AUTOSAR XML (schema 314)
package /ComponentType
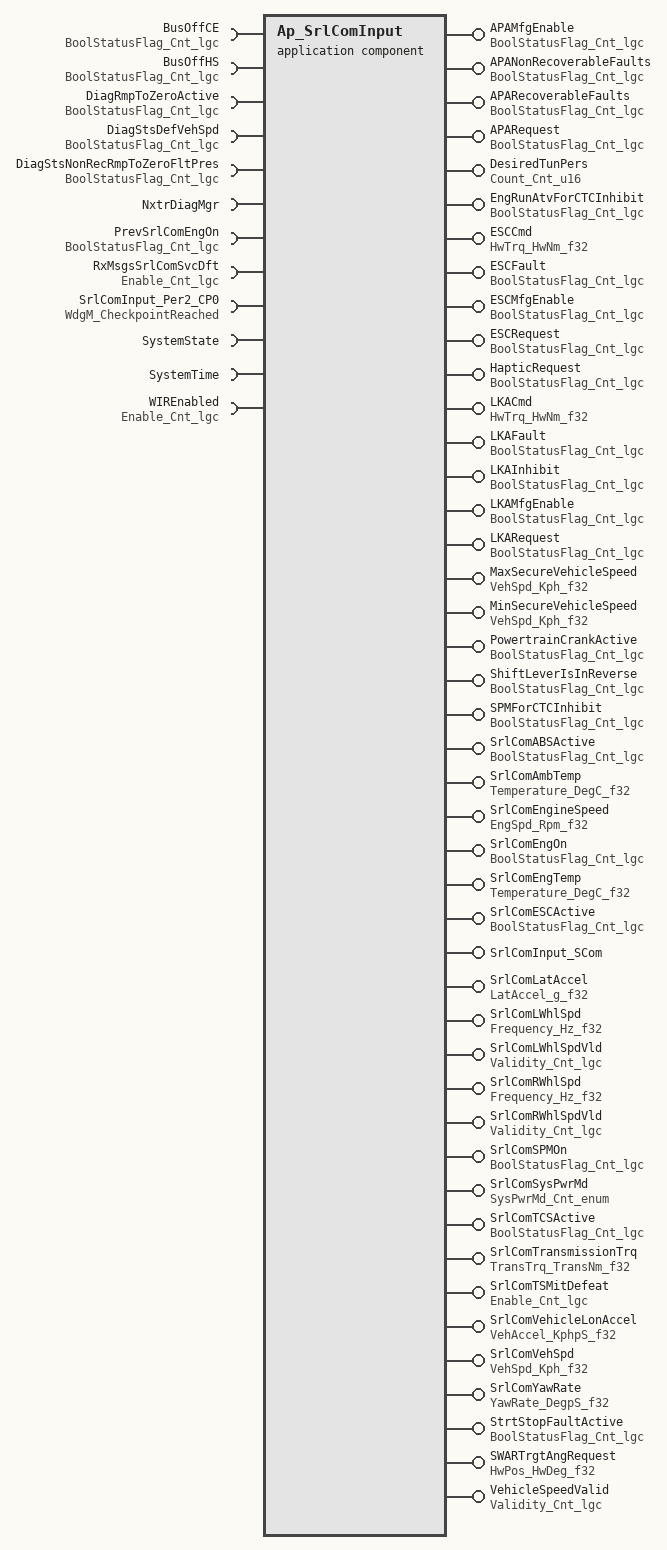
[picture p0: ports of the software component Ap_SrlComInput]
  application software component type Ap_SrlComInput
    44 x provide port:
      APAMfgEnable: unqueued-sender-com-spec{data-element=Cnt_lgc, can-invalidate=false, init-value=D_FALSE_CNT_LGC}, provided-interface=BoolStatusFlag_Cnt_lgc
      APANonRecoverableFaults: unqueued-sender-com-spec{data-element=Cnt_lgc, can-invalidate=false, init-value=D_FALSE_CNT_LGC}, provided-interface=BoolStatusFlag_Cnt_lgc
      APARecoverableFaults: unqueued-sender-com-spec{data-element=Cnt_lgc, can-invalidate=false, init-value=D_FALSE_CNT_LGC}, provided-interface=BoolStatusFlag_Cnt_lgc
      APARequest: unqueued-sender-com-spec{data-element=Cnt_lgc, can-invalidate=false, init-value=D_FALSE_CNT_LGC}, provided-interface=BoolStatusFlag_Cnt_lgc
      DesiredTunPers: unqueued-sender-com-spec{data-element=Cnt_u16, can-invalidate=false, init-value=D_ZERO_CNT_U16}, provided-interface=Count_Cnt_u16
      EngRunAtvForCTCInhibit: unqueued-sender-com-spec{data-element=Cnt_lgc, can-invalidate=false, init-value=D_FALSE_CNT_LGC}, provided-interface=BoolStatusFlag_Cnt_lgc
      ESCCmd: unqueued-sender-com-spec{data-element=HwNm_f32, can-invalidate=false, init-value=D_ZERO_ULS_F32}, provided-interface=HwTrq_HwNm_f32
      ESCFault: unqueued-sender-com-spec{data-element=Cnt_lgc, can-invalidate=false, init-value=D_FALSE_CNT_LGC}, provided-interface=BoolStatusFlag_Cnt_lgc
      ESCMfgEnable: unqueued-sender-com-spec{data-element=Cnt_lgc, can-invalidate=false, init-value=D_FALSE_CNT_LGC}, provided-interface=BoolStatusFlag_Cnt_lgc
      ESCRequest: unqueued-sender-com-spec{data-element=Cnt_lgc, can-invalidate=false, init-value=D_FALSE_CNT_LGC}, provided-interface=BoolStatusFlag_Cnt_lgc
      HapticRequest: unqueued-sender-com-spec{data-element=Cnt_lgc, can-invalidate=false, init-value=D_FALSE_CNT_LGC}, provided-interface=BoolStatusFlag_Cnt_lgc
      LKACmd: unqueued-sender-com-spec{data-element=HwNm_f32, can-invalidate=false, init-value=D_ZERO_ULS_F32}, provided-interface=HwTrq_HwNm_f32
      LKAFault: unqueued-sender-com-spec{data-element=Cnt_lgc, can-invalidate=false, init-value=D_FALSE_CNT_LGC}, provided-interface=BoolStatusFlag_Cnt_lgc
      LKAInhibit: unqueued-sender-com-spec{data-element=Cnt_lgc, can-invalidate=false, init-value=D_FALSE_CNT_LGC}, provided-interface=BoolStatusFlag_Cnt_lgc
      LKAMfgEnable: unqueued-sender-com-spec{data-element=Cnt_lgc, can-invalidate=false, init-value=D_FALSE_CNT_LGC}, provided-interface=BoolStatusFlag_Cnt_lgc
      LKARequest: unqueued-sender-com-spec{data-element=Cnt_lgc, can-invalidate=false, init-value=D_FALSE_CNT_LGC}, provided-interface=BoolStatusFlag_Cnt_lgc
      MaxSecureVehicleSpeed: unqueued-sender-com-spec{data-element=Kph_f32, can-invalidate=false, init-value=D_ZERO_ULS_F32}, provided-interface=VehSpd_Kph_f32
      MinSecureVehicleSpeed: unqueued-sender-com-spec{data-element=Kph_f32, can-invalidate=false, init-value=D_ZERO_ULS_F32}, provided-interface=VehSpd_Kph_f32
      PowertrainCrankActive: unqueued-sender-com-spec{data-element=Cnt_lgc, can-invalidate=false, init-value=D_FALSE_CNT_LGC}, provided-interface=BoolStatusFlag_Cnt_lgc
      ShiftLeverIsInReverse: unqueued-sender-com-spec{data-element=Cnt_lgc, can-invalidate=false, init-value=D_FALSE_CNT_LGC}, provided-interface=BoolStatusFlag_Cnt_lgc
      SPMForCTCInhibit: unqueued-sender-com-spec{data-element=Cnt_lgc, can-invalidate=false, init-value=D_FALSE_CNT_LGC}, provided-interface=BoolStatusFlag_Cnt_lgc
      SrlComABSActive: unqueued-sender-com-spec{data-element=Cnt_lgc, can-invalidate=false, init-value=D_FALSE_CNT_LGC}, provided-interface=BoolStatusFlag_Cnt_lgc
      SrlComAmbTemp: unqueued-sender-com-spec{data-element=DegC_f32, can-invalidate=false, init-value=D_ZERO_ULS_F32}, provided-interface=Temperature_DegC_f32
      SrlComEngineSpeed: unqueued-sender-com-spec{data-element=Rpm_f32, can-invalidate=false, init-value=D_ZERO_ULS_F32}, provided-interface=EngSpd_Rpm_f32
      SrlComEngOn: unqueued-sender-com-spec{data-element=Cnt_lgc, can-invalidate=false, init-value=D_FALSE_CNT_LGC}, provided-interface=BoolStatusFlag_Cnt_lgc
      SrlComEngTemp: unqueued-sender-com-spec{data-element=DegC_f32, can-invalidate=false, init-value=D_ZERO_ULS_F32}, provided-interface=Temperature_DegC_f32
      SrlComESCActive: unqueued-sender-com-spec{data-element=Cnt_lgc, can-invalidate=false, init-value=D_FALSE_CNT_LGC}, provided-interface=BoolStatusFlag_Cnt_lgc
      SrlComInput_SCom: provided-interface=SrlComInput_SCom
        provided-com-specs:
          operation=GetSrlComWIRFltStatus, queue-length=1
          operation=ManualVehSpd, queue-length=1
          operation=ResetBus1Timers, queue-length=1
          operation=ResetBus2Timers, queue-length=1
      SrlComLatAccel: unqueued-sender-com-spec{data-element=g_f32, can-invalidate=false, init-value=D_ZERO_ULS_F32}, provided-interface=LatAccel_g_f32
      SrlComLWhlSpd: unqueued-sender-com-spec{data-element=Hz_f32, can-invalidate=false, init-value=D_ZERO_ULS_F32}, provided-interface=Frequency_Hz_f32
      SrlComLWhlSpdVld: unqueued-sender-com-spec{data-element=Cnt_lgc, can-invalidate=false, init-value=D_FALSE_CNT_LGC}, provided-interface=Validity_Cnt_lgc
      SrlComRWhlSpd: unqueued-sender-com-spec{data-element=Hz_f32, can-invalidate=false, init-value=D_ZERO_ULS_F32}, provided-interface=Frequency_Hz_f32
      SrlComRWhlSpdVld: unqueued-sender-com-spec{data-element=Cnt_lgc, can-invalidate=false, init-value=D_FALSE_CNT_LGC}, provided-interface=Validity_Cnt_lgc
      SrlComSPMOn: unqueued-sender-com-spec{data-element=Cnt_lgc, can-invalidate=false, init-value=D_FALSE_CNT_LGC}, provided-interface=BoolStatusFlag_Cnt_lgc
      SrlComSysPwrMd: unqueued-sender-com-spec{data-element=Cnt_enum, can-invalidate=false, init-value=D_SYSPWRMODESTATEINIT_CNT_ENUM}, provided-interface=SysPwrMd_Cnt_enum
      SrlComTCSActive: unqueued-sender-com-spec{data-element=Cnt_lgc, can-invalidate=false, init-value=D_FALSE_CNT_LGC}, provided-interface=BoolStatusFlag_Cnt_lgc
      SrlComTransmissionTrq: unqueued-sender-com-spec{data-element=TransNm_f32, can-invalidate=false, init-value=D_ZERO_ULS_F32}, provided-interface=TransTrq_TransNm_f32
      SrlComTSMitDefeat: unqueued-sender-com-spec{data-element=Cnt_lgc, can-invalidate=false, init-value=D_FALSE_CNT_LGC}, provided-interface=Enable_Cnt_lgc
      SrlComVehicleLonAccel: unqueued-sender-com-spec{data-element=KphpS_f32, can-invalidate=false, init-value=D_ZERO_ULS_F32}, provided-interface=VehAccel_KphpS_f32
      SrlComVehSpd: unqueued-sender-com-spec{data-element=Kph_f32, can-invalidate=false, init-value=D_ZERO_ULS_F32}, provided-interface=VehSpd_Kph_f32
      SrlComYawRate: unqueued-sender-com-spec{data-element=DegpS_f32, can-invalidate=false, init-value=D_ZERO_ULS_F32}, provided-interface=YawRate_DegpS_f32
      StrtStopFaultActive: unqueued-sender-com-spec{data-element=Cnt_lgc, can-invalidate=false, init-value=D_FALSE_CNT_LGC}, provided-interface=BoolStatusFlag_Cnt_lgc
      SWARTrgtAngRequest: unqueued-sender-com-spec{data-element=HwDeg_f32, can-invalidate=false, init-value=D_ZERO_ULS_F32}, provided-interface=HwPos_HwDeg_f32
      VehicleSpeedValid: unqueued-sender-com-spec{data-element=Cnt_lgc, can-invalidate=false, init-value=D_FALSE_CNT_LGC}, provided-interface=Validity_Cnt_lgc
    12 x require port:
      BusOffCE: unqueued-receiver-com-spec{data-element=Cnt_lgc, init-value=D_FALSE_CNT_LGC}, required-interface=BoolStatusFlag_Cnt_lgc
      BusOffHS: unqueued-receiver-com-spec{data-element=Cnt_lgc, init-value=D_FALSE_CNT_LGC}, required-interface=BoolStatusFlag_Cnt_lgc
      DiagRmpToZeroActive: unqueued-receiver-com-spec{data-element=Cnt_lgc, init-value=D_FALSE_CNT_LGC}, required-interface=BoolStatusFlag_Cnt_lgc
      DiagStsDefVehSpd: unqueued-receiver-com-spec{data-element=Cnt_lgc, init-value=D_FALSE_CNT_LGC}, required-interface=BoolStatusFlag_Cnt_lgc
      DiagStsNonRecRmpToZeroFltPres: unqueued-receiver-com-spec{data-element=Cnt_lgc, init-value=D_FALSE_CNT_LGC}, required-interface=BoolStatusFlag_Cnt_lgc
      NxtrDiagMgr: required-com-specs=[GetNTCActive, GetNTCFailed, GetNTCStatus, SetNTCStatus], required-interface=NxtrDiagMgr
      PrevSrlComEngOn: unqueued-receiver-com-spec{data-element=Cnt_lgc, init-value=D_FALSE_CNT_LGC}, required-interface=BoolStatusFlag_Cnt_lgc
      RxMsgsSrlComSvcDft: unqueued-receiver-com-spec{data-element=Cnt_lgc, init-value=D_FALSE_CNT_LGC}, required-interface=Enable_Cnt_lgc
      SrlComInput_Per2_CP0: client-com-spec=CheckpointReached, required-interface=WdgM_CheckpointReached
      SystemState: required-interface=SystemState
      SystemTime: required-interface=SystemTime
        required-com-specs:
          DtrmnElapsedTime_mS_u16
          DtrmnElapsedTime_mS_u32
          DtrmnElapsedTime_uS_u16
          DtrmnElapsedTime_uS_u32
          GetSystemTime_mS_u32
          GetSystemTime_uS_u32
      WIREnabled: unqueued-receiver-com-spec{data-element=Cnt_lgc, init-value=D_FALSE_CNT_LGC}, required-interface=Enable_Cnt_lgc
  internal behavior Ap_SrlComInput_InternalBehavior: component=Ap_SrlComInput
    4 x timing event:
      SrlComInput_InitEvent: start-on-event=SrlComInput_Init, period=0
      TMT_SrlComInput_Per1: start-on-event=SrlComInput_Per1, period=0.002
      TMT_SrlComInput_Per2: start-on-event=SrlComInput_Per2, period=0.01
      TMT_SrlComInput_Per3: start-on-event=SrlComInput_Per3, period=0.1
    4 x operation invoked event:
      OIT_SrlComInput_SCom_GetSrlComWIRFltStatus_SrlComInput_SCom_GetSrlComWIRFltStatus: start-on-event=SrlComInput_SCom_GetSrlComWIRFltStatus, operation=SrlComInput_SCom.GetSrlComWIRFltStatus
      OIT_SrlComInput_SCom_ManualVehSpd_SrlComInput_SCom_ManualVehSpd: start-on-event=SrlComInput_SCom_ManualVehSpd, operation=SrlComInput_SCom.ManualVehSpd
      OIT_SrlComInput_SCom_ResetBus1Timers_SrlComInput_SCom_ResetBus1Timers: start-on-event=SrlComInput_SCom_ResetBus1Timers, operation=SrlComInput_SCom.ResetBus1Timers
      OIT_SrlComInput_SCom_ResetBus2Timers_SrlComInput_SCom_ResetBus2Timers: start-on-event=SrlComInput_SCom_ResetBus2Timers, operation=SrlComInput_SCom.ResetBus2Timers
    port-api-options:
      enable-take-address=false, indirect-api=false, port=APAMfgEnable
      enable-take-address=false, indirect-api=false, port=APANonRecoverableFaults
      enable-take-address=false, indirect-api=false, port=APARecoverableFaults
      enable-take-address=false, indirect-api=false, port=APARequest
      enable-take-address=false, indirect-api=false, port=BusOffCE
      enable-take-address=false, indirect-api=false, port=BusOffHS
      enable-take-address=false, indirect-api=false, port=DesiredTunPers
      enable-take-address=false, indirect-api=false, port=DiagRmpToZeroActive
      enable-take-address=false, indirect-api=false, port=DiagStsDefVehSpd
      enable-take-address=false, indirect-api=false, port=DiagStsNonRecRmpToZeroFltPres
      enable-take-address=false, indirect-api=false, port=EngRunAtvForCTCInhibit
      enable-take-address=false, indirect-api=false, port=ESCCmd
      enable-take-address=false, indirect-api=false, port=ESCFault
      enable-take-address=false, indirect-api=false, port=ESCMfgEnable
      enable-take-address=false, indirect-api=false, port=ESCRequest
      enable-take-address=false, indirect-api=false, port=HapticRequest
      enable-take-address=false, indirect-api=false, port=LKACmd
      enable-take-address=false, indirect-api=false, port=LKAFault
      enable-take-address=false, indirect-api=false, port=LKAInhibit
      enable-take-address=false, indirect-api=false, port=LKAMfgEnable
      enable-take-address=false, indirect-api=false, port=LKARequest
      enable-take-address=false, indirect-api=false, port=MaxSecureVehicleSpeed
      enable-take-address=false, indirect-api=false, port=MinSecureVehicleSpeed
      enable-take-address=false, indirect-api=false, port=NxtrDiagMgr
      enable-take-address=false, indirect-api=false, port=PowertrainCrankActive
      enable-take-address=false, indirect-api=false, port=PrevSrlComEngOn
      enable-take-address=false, indirect-api=false, port=RxMsgsSrlComSvcDft
      enable-take-address=false, indirect-api=false, port=ShiftLeverIsInReverse
      enable-take-address=false, indirect-api=false, port=SPMForCTCInhibit
      enable-take-address=false, indirect-api=false, port=SrlComABSActive
      enable-take-address=false, indirect-api=false, port=SrlComAmbTemp
      enable-take-address=false, indirect-api=false, port=SrlComEngineSpeed
      enable-take-address=false, indirect-api=false, port=SrlComEngOn
      enable-take-address=false, indirect-api=false, port=SrlComEngTemp
      enable-take-address=false, indirect-api=false, port=SrlComESCActive
      enable-take-address=false, indirect-api=false, port=SrlComInput_Per2_CP0
      enable-take-address=false, indirect-api=false, port=SrlComInput_SCom
      enable-take-address=false, indirect-api=false, port=SrlComLatAccel
      enable-take-address=false, indirect-api=false, port=SrlComLWhlSpd
      enable-take-address=false, indirect-api=false, port=SrlComLWhlSpdVld
      enable-take-address=false, indirect-api=false, port=SrlComRWhlSpd
      enable-take-address=false, indirect-api=false, port=SrlComRWhlSpdVld
      enable-take-address=false, indirect-api=false, port=SrlComSPMOn
      enable-take-address=false, indirect-api=false, port=SrlComSysPwrMd
      enable-take-address=false, indirect-api=false, port=SrlComTCSActive
      enable-take-address=false, indirect-api=false, port=SrlComTransmissionTrq
      enable-take-address=false, indirect-api=false, port=SrlComTSMitDefeat
      enable-take-address=false, indirect-api=false, port=SrlComVehicleLonAccel
      enable-take-address=false, indirect-api=false, port=SrlComVehSpd
      enable-take-address=false, indirect-api=false, port=SrlComYawRate
      enable-take-address=false, indirect-api=false, port=StrtStopFaultActive
      enable-take-address=false, indirect-api=false, port=SWARTrgtAngRequest
      enable-take-address=false, indirect-api=false, port=SystemState
      enable-take-address=false, indirect-api=false, port=SystemTime
      enable-take-address=false, indirect-api=false, port=VehicleSpeedValid
      enable-take-address=false, indirect-api=false, port=WIREnabled
    8 x runnable:
      SrlComInput_Init
        data send point SEND_SrlComAmbTemp_DegC_f32: data-element=SrlComAmbTemp.DegC_f32
        data send point SEND_SrlComEngTemp_DegC_f32: data-element=SrlComEngTemp.DegC_f32
        data send point SEND_SrlComVehicleLonAccel_KphpS_f32: data-element=SrlComVehicleLonAccel.KphpS_f32
      SrlComInput_Per1
        data receive point REC_RxMsgsSrlComSvcDft_Cnt_lgc: data-element=RxMsgsSrlComSvcDft.Cnt_lgc
        data receive point REC_WIREnabled_Cnt_lgc: data-element=WIREnabled.Cnt_lgc
        9 x data send point:
          SEND_LKACmd_HwNm_f32: data-element=LKACmd.HwNm_f32
          SEND_LKAFault_Cnt_lgc: data-element=LKAFault.Cnt_lgc
          SEND_LKAInhibit_Cnt_lgc: data-element=LKAInhibit.Cnt_lgc
          SEND_LKARequest_Cnt_lgc: data-element=LKARequest.Cnt_lgc
          SEND_MaxSecureVehicleSpeed_Kph_f32: data-element=MaxSecureVehicleSpeed.Kph_f32
          SEND_SrlComLWhlSpd_Hz_f32: data-element=SrlComLWhlSpd.Hz_f32
          SEND_SrlComLWhlSpdVld_Cnt_lgc: data-element=SrlComLWhlSpdVld.Cnt_lgc
          SEND_SrlComRWhlSpd_Hz_f32: data-element=SrlComRWhlSpd.Hz_f32
          SEND_SrlComRWhlSpdVld_Cnt_lgc: data-element=SrlComRWhlSpdVld.Cnt_lgc
        sync call SC_NxtrDiagMgr_GetNTCStatus: operation=NxtrDiagMgr.GetNTCStatus, timeout=0
        sync call SC_NxtrDiagMgr_SetNTCStatus: operation=NxtrDiagMgr.SetNTCStatus, timeout=0
        sync call SC_SystemTime_GetSystemTime_mS_u32: operation=SystemTime.GetSystemTime_mS_u32, timeout=0
      SrlComInput_Per2
        data read access READ_BusOffCE_Cnt_lgc: data-element=BusOffCE.Cnt_lgc
        data read access READ_BusOffHS_Cnt_lgc: data-element=BusOffHS.Cnt_lgc
        4 x data receive point:
          REC_DiagRmpToZeroActive_Cnt_lgc: data-element=DiagRmpToZeroActive.Cnt_lgc
          REC_DiagStsNonRecRmpToZeroFltPres_Cnt_lgc: data-element=DiagStsNonRecRmpToZeroFltPres.Cnt_lgc
          REC_RxMsgsSrlComSvcDft_Cnt_lgc: data-element=RxMsgsSrlComSvcDft.Cnt_lgc
          REC_WIREnabled_Cnt_lgc: data-element=WIREnabled.Cnt_lgc
        37 x data send point:
          SEND_APAMfgEnable_Cnt_lgc: data-element=APAMfgEnable.Cnt_lgc
          SEND_APANonRecoverableFaults_Cnt_lgc: data-element=APANonRecoverableFaults.Cnt_lgc
          SEND_APARecoverableFaults_Cnt_lgc: data-element=APARecoverableFaults.Cnt_lgc
          SEND_APARequest_Cnt_lgc: data-element=APARequest.Cnt_lgc
          SEND_DesiredTunPers_Cnt_u16: data-element=DesiredTunPers.Cnt_u16
          SEND_EngRunAtvForCTCInhibit_Cnt_lgc: data-element=EngRunAtvForCTCInhibit.Cnt_lgc
          SEND_ESCCmd_HwNm_f32: data-element=ESCCmd.HwNm_f32
          SEND_ESCFault_Cnt_lgc: data-element=ESCFault.Cnt_lgc
          SEND_ESCMfgEnable_Cnt_lgc: data-element=ESCMfgEnable.Cnt_lgc
          SEND_ESCRequest_Cnt_lgc: data-element=ESCRequest.Cnt_lgc
          SEND_HapticRequest_Cnt_lgc: data-element=HapticRequest.Cnt_lgc
          SEND_LKACmd_HwNm_f32: data-element=LKACmd.HwNm_f32
          SEND_LKAFault_Cnt_lgc: data-element=LKAFault.Cnt_lgc
          SEND_LKAInhibit_Cnt_lgc: data-element=LKAInhibit.Cnt_lgc
          SEND_LKAMfgEnable_Cnt_lgc: data-element=LKAMfgEnable.Cnt_lgc
          SEND_LKARequest_Cnt_lgc: data-element=LKARequest.Cnt_lgc
          SEND_MaxSecureVehicleSpeed_Kph_f32: data-element=MaxSecureVehicleSpeed.Kph_f32
          SEND_MinSecureVehicleSpeed_Kph_f32: data-element=MinSecureVehicleSpeed.Kph_f32
          SEND_PowertrainCrankActive_Cnt_lgc: data-element=PowertrainCrankActive.Cnt_lgc
          SEND_ShiftLeverIsInReverse_Cnt_lgc: data-element=ShiftLeverIsInReverse.Cnt_lgc
          SEND_SPMForCTCInhibit_Cnt_lgc: data-element=SPMForCTCInhibit.Cnt_lgc
          SEND_SrlComABSActive_Cnt_lgc: data-element=SrlComABSActive.Cnt_lgc
          SEND_SrlComEngineSpeed_Rpm_f32: data-element=SrlComEngineSpeed.Rpm_f32
          SEND_SrlComEngOn_Cnt_lgc: data-element=SrlComEngOn.Cnt_lgc
          SEND_SrlComESCActive_Cnt_lgc: data-element=SrlComESCActive.Cnt_lgc
          SEND_SrlComLatAccel_g_f32: data-element=SrlComLatAccel.g_f32
          SEND_SrlComLWhlSpd_Hz_f32: data-element=SrlComLWhlSpd.Hz_f32
          SEND_SrlComLWhlSpdVld_Cnt_lgc: data-element=SrlComLWhlSpdVld.Cnt_lgc
          SEND_SrlComRWhlSpd_Hz_f32: data-element=SrlComRWhlSpd.Hz_f32
          SEND_SrlComRWhlSpdVld_Cnt_lgc: data-element=SrlComRWhlSpdVld.Cnt_lgc
          SEND_SrlComSysPwrMd_Cnt_enum: data-element=SrlComSysPwrMd.Cnt_enum
          SEND_SrlComTCSActive_Cnt_lgc: data-element=SrlComTCSActive.Cnt_lgc
          SEND_SrlComTransmissionTrq_TransNm_f32: data-element=SrlComTransmissionTrq.TransNm_f32
          SEND_SrlComTSMitDefeat_Cnt_lgc: data-element=SrlComTSMitDefeat.Cnt_lgc
          SEND_SrlComYawRate_DegpS_f32: data-element=SrlComYawRate.DegpS_f32
          SEND_StrtStopFaultActive_Cnt_lgc: data-element=StrtStopFaultActive.Cnt_lgc
          SEND_SWARTrgtAngRequest_HwDeg_f32: data-element=SWARTrgtAngRequest.HwDeg_f32
        5 x sync call, all with timeout=0:
          SC_NxtrDiagMgr_GetNTCActive: operation=NxtrDiagMgr.GetNTCActive
          SC_NxtrDiagMgr_SetNTCStatus: operation=NxtrDiagMgr.SetNTCStatus
          SC_SrlComInput_Per2_CP0_CheckpointReached: operation=SrlComInput_Per2_CP0.CheckpointReached
          SC_SystemTime_DtrmnElapsedTime_mS_u16: operation=SystemTime.DtrmnElapsedTime_mS_u16
          SC_SystemTime_GetSystemTime_mS_u32: operation=SystemTime.GetSystemTime_mS_u32
      SrlComInput_Per3
        4 x data receive point:
          REC_DiagStsDefVehSpd_Cnt_lgc: data-element=DiagStsDefVehSpd.Cnt_lgc
          REC_PrevSrlComEngOn_Cnt_lgc: data-element=PrevSrlComEngOn.Cnt_lgc
          REC_RxMsgsSrlComSvcDft_Cnt_lgc: data-element=RxMsgsSrlComSvcDft.Cnt_lgc
          REC_WIREnabled_Cnt_lgc: data-element=WIREnabled.Cnt_lgc
        7 x data send point:
          SEND_SPMForCTCInhibit_Cnt_lgc: data-element=SPMForCTCInhibit.Cnt_lgc
          SEND_SrlComAmbTemp_DegC_f32: data-element=SrlComAmbTemp.DegC_f32
          SEND_SrlComEngTemp_DegC_f32: data-element=SrlComEngTemp.DegC_f32
          SEND_SrlComSPMOn_Cnt_lgc: data-element=SrlComSPMOn.Cnt_lgc
          SEND_SrlComSysPwrMd_Cnt_enum: data-element=SrlComSysPwrMd.Cnt_enum
          SEND_SrlComVehSpd_Kph_f32: data-element=SrlComVehSpd.Kph_f32
          SEND_VehicleSpeedValid_Cnt_lgc: data-element=VehicleSpeedValid.Cnt_lgc
        sync call SC_NxtrDiagMgr_SetNTCStatus: operation=NxtrDiagMgr.SetNTCStatus, timeout=0
        sync call SC_SystemTime_GetSystemTime_mS_u32: operation=SystemTime.GetSystemTime_mS_u32, timeout=0
      SrlComInput_SCom_GetSrlComWIRFltStatus
      SrlComInput_SCom_ManualVehSpd
      SrlComInput_SCom_ResetBus1Timers: can-be-invoked-concurrently=true
        sync call SC_SystemTime_GetSystemTime_mS_u32: operation=SystemTime.GetSystemTime_mS_u32, timeout=0
      SrlComInput_SCom_ResetBus2Timers: can-be-invoked-concurrently=true
        sync call SC_SystemTime_GetSystemTime_mS_u32: operation=SystemTime.GetSystemTime_mS_u32, timeout=0
  swc implementation Ap_SrlComInput_Implementation: behavior=Ap_SrlComInput_InternalBehavior
    code-descriptors:
      code Code: type=SRC
